# STM32U535 register map
File version: 0.4
CPU: CM33 r0p1, little endian, MPU, FPU, 4 interrupt priority bits
Registers are 32-bit, read-write, reset 0x0 unless marked. A register's access mark holds for its fields unless they carry their own. Offsets are from the block's base; [hi:lo] are bit positions; {n}, {i} and the like mark numbered series.

## ICache
Base 0x40030400
Same registers: SEC_ICache 0x50030400
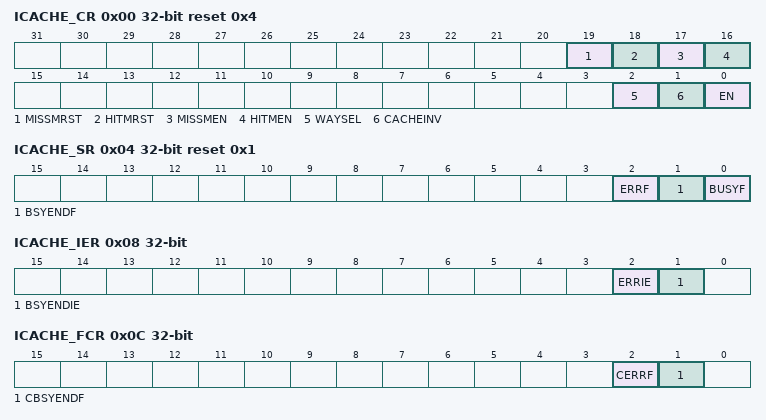
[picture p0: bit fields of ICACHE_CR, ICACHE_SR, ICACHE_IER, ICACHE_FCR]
0x00 ICACHE_CR access per field reset 0x4 — ICACHE control register
  [19] MISSMRST rw, [18] HITMRST rw, [17] MISSMEN rw, [16] HITMEN rw, [2] WAYSEL rw, [1] CACHEINV wo, [0] EN rw
0x04 ICACHE_SR ro reset 0x1 — ICACHE status register
  [2] ERRF, [1] BSYENDF, [0] BUSYF
0x08 ICACHE_IER — ICACHE interrupt enable register
  [2] ERRIE, [1] BSYENDIE
0x0C ICACHE_FCR wo — ICACHE flag clear register
  [2] CERRF, [1] CBSYENDF
0x10 ICACHE_HMONR ro — ICACHE hit monitor register
  [31:0] HITMON
0x14 ICACHE_MMONR ro — ICACHE miss monitor register
  [15:0] MISSMON
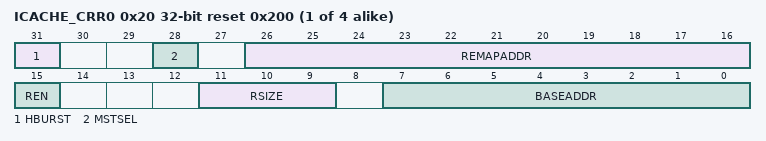
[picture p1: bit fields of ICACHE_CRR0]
{0x20+4i} ICACHE_CRR{i} reset 0x200 (i=0..3) — ICACHE region configuration register
  [31] HBURST, [28] MSTSEL, [26:16] REMAPADDR, [15] REN, [11:9] RSIZE, [7:0] BASEADDR

## IWDG — Independent watchdog
Base 0x40003000
Same registers: SEC_IWDG 0x50003000
0x00 KR wo — Key register
  [15:0] KEY — Key value (write only, read 0x0000)
0x04 PR — Prescaler register
  [3:0] PR — Prescaler divider
0x08 RLR reset 0xFFF — Reload register
  [11:0] RL — Watchdog counter reload value
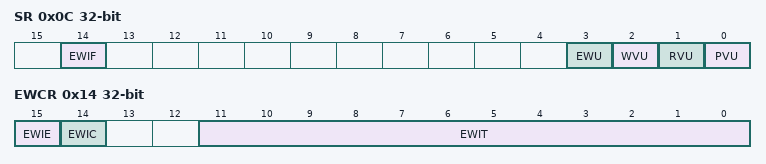
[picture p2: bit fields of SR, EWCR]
0x0C SR ro — Status register
  [14] EWIF — Watchdog Early interrupt flag
  [3] EWU — Watchdog interrupt comparator value update
  [2] WVU — Watchdog counter window value update
  [1] RVU — Watchdog counter reload value update
  [0] PVU — Watchdog prescaler value update
0x10 WINR reset 0xFFF — Window register
  [11:0] WIN — Watchdog counter window value
0x14 EWCR — IWDG early wakeup interrupt register
  [15] EWIE — Watchdog early interrupt enable
  [14] EWIC — Watchdog early interrupt acknowledge
  [11:0] EWIT — Watchdog counter window value

## LPGPIO1
Base 0x46020000
Same registers: SEC_LPGPIO1 0x56020000
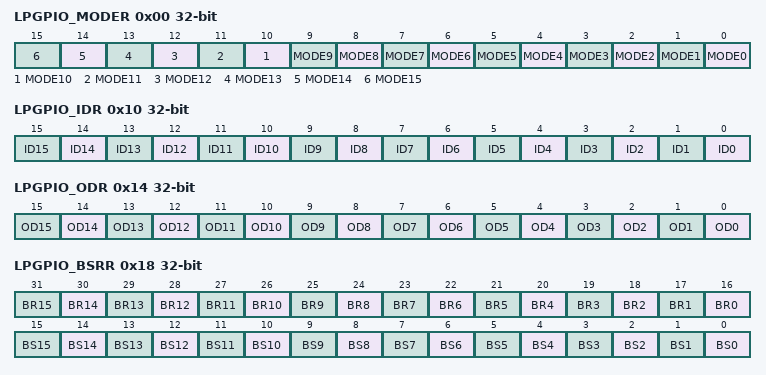
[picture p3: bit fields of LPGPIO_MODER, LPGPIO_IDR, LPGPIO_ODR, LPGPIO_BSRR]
0x00 LPGPIO_MODER — LPGPIO port mode register
  [n] MODE{n} (n=0..15)
0x10 LPGPIO_IDR ro — LPGPIO port input data register
  [n] ID{n} (n=0..15)
0x14 LPGPIO_ODR — LPGPIO port output data register
  [n] OD{n} (n=0..15)
0x18 LPGPIO_BSRR wo — LPGPIO port bit set/reset register
  [n+16] BR{n} (n=0..15), [n] BS{n} (n=0..15)
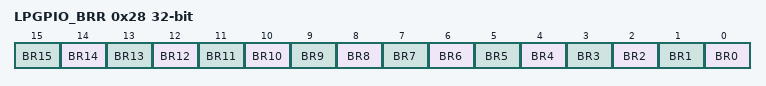
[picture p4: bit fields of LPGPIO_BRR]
0x28 LPGPIO_BRR wo — LPGPIO port bit reset register
  [n] BR{n} (n=0..15)

## LPUART1 — Universal synchronous asynchronous receiver transmitter
Base 0x46002400
Same registers: SEC_LPUART1 0x56002400
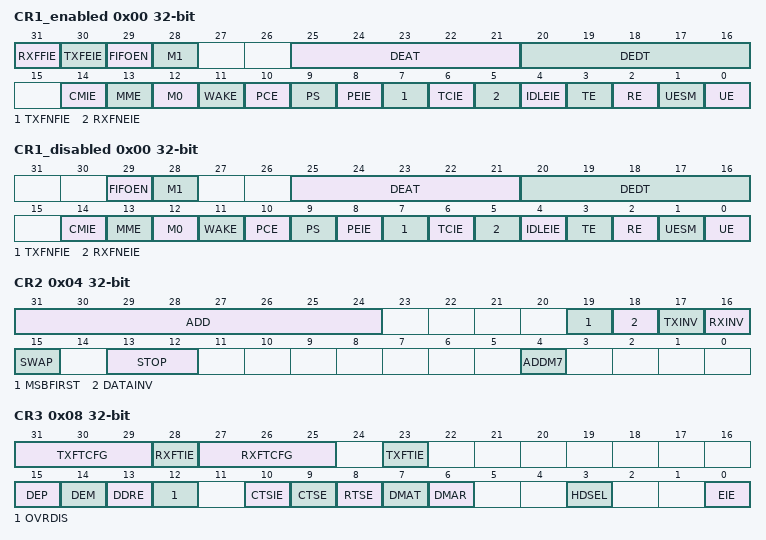
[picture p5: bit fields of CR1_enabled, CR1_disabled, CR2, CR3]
0x00 CR1_enabled — Control register 1
  [31] RXFFIE
  [30] TXFEIE
  [29] FIFOEN
  [28] M1 — Word length
  [25:21] DEAT
  [20:16] DEDT
  [14] CMIE — Character match interrupt enable
  [13] MME — Mute mode enable
  [12] M0 — Word length
  [11] WAKE — Receiver wakeup method
  [10] PCE — Parity control enable
  [9] PS — Parity selection
  [8] PEIE — PE interrupt enable
  [7] TXFNFIE — TXFIFO not full interrupt enable
  [6] TCIE — Transmission complete interrupt enable
  [5] RXFNEIE
  [4] IDLEIE — IDLE interrupt enable
  [3] TE — Transmitter enable
  [2] RE — Receiver enable
  [1] UESM — USART enable in Stop mode
  [0] UE — USART enable
0x00 CR1_disabled (alternate view of CR1_enabled) — Control register 1
  [29] FIFOEN
  [28] M1 — Word length
  [25:21] DEAT
  [20:16] DEDT
  [14] CMIE — Character match interrupt enable
  [13] MME — Mute mode enable
  [12] M0 — Word length
  [11] WAKE — Receiver wakeup method
  [10] PCE — Parity control enable
  [9] PS — Parity selection
  [8] PEIE — PE interrupt enable
  [7] TXFNFIE — TXFIFO not full interrupt enable
  [6] TCIE — Transmission complete interrupt enable
  [5] RXFNEIE
  [4] IDLEIE — IDLE interrupt enable
  [3] TE — Transmitter enable
  [2] RE — Receiver enable
  [1] UESM — USART enable in Stop mode
  [0] UE — USART enable
0x04 CR2 — Control register 2
  [31:24] ADD — Address of the LPUART node
  [19] MSBFIRST — Most significant bit first
  [18] DATAINV — Binary data inversion
  [17] TXINV — TX pin active level inversion
  [16] RXINV — RX pin active level inversion
  [15] SWAP — Swap TX/RX pins
  [13:12] STOP — STOP bits
  [4] ADDM7 — 7-bit Address Detection/4-bit Address Detection
0x08 CR3 — Control register 3
  [31:29] TXFTCFG
  [28] RXFTIE
  [27:25] RXFTCFG
  [23] TXFTIE
  [15] DEP — Driver enable polarity selection
  [14] DEM — Driver enable mode
  [13] DDRE — DMA Disable on Reception Error
  [12] OVRDIS — Overrun Disable
  [10] CTSIE — CTS interrupt enable
  [9] CTSE — CTS enable
  [8] RTSE — RTS enable
  [7] DMAT — DMA enable transmitter
  [6] DMAR — DMA enable receiver
  [3] HDSEL — Half-duplex selection
  [0] EIE — Error interrupt enable
0x0C BRR — Baud rate register
  [19:0] BRR
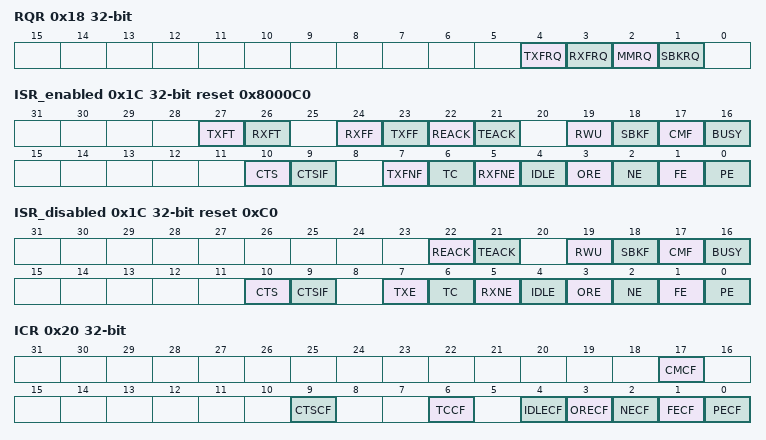
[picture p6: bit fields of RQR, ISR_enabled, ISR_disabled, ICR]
0x18 RQR wo — Request register
  [4] TXFRQ
  [3] RXFRQ — Receive data flush request
  [2] MMRQ — Mute mode request
  [1] SBKRQ — Send break request
0x1C ISR_enabled ro reset 0x8000C0 — Interrupt and status register
  [27] TXFT, [26] RXFT, [24] RXFF, [23] TXFF, [22] REACK, [21] TEACK, [19] RWU, [18] SBKF, [17] CMF, [16] BUSY, [10] CTS, [9] CTSIF, [7] TXFNF, [6] TC, [5] RXFNE, [4] IDLE, [3] ORE, [2] NE, [1] FE, [0] PE
0x1C ISR_disabled ro reset 0xC0 (alternate view of ISR_enabled) — Interrupt and status register
  [22] REACK, [21] TEACK, [19] RWU, [18] SBKF, [17] CMF, [16] BUSY, [10] CTS, [9] CTSIF, [7] TXE, [6] TC, [5] RXNE, [4] IDLE, [3] ORE, [2] NE, [1] FE, [0] PE
0x20 ICR wo — Interrupt flag clear register
  [17] CMCF — Character match clear flag
  [9] CTSCF — CTS clear flag
  [6] TCCF — Transmission complete clear flag
  [4] IDLECF — Idle line detected clear flag
  [3] ORECF — Overrun error clear flag
  [2] NECF — Noise detected clear flag
  [1] FECF — Framing error clear flag
  [0] PECF — Parity error clear flag
0x24 RDR ro — Receive data register
  [8:0] RDR — Receive data value
0x28 TDR — Transmit data register
  [8:0] TDR — Transmit data value
0x2C PRESC — prescaler register
  [3:0] PRESCALER
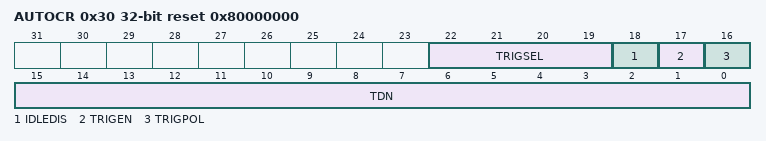
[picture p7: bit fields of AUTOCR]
0x30 AUTOCR reset 0x80000000 — Autonomous mode control register
  [22:19] TRIGSEL, [18] IDLEDIS, [17] TRIGEN, [16] TRIGPOL, [15:0] TDN
